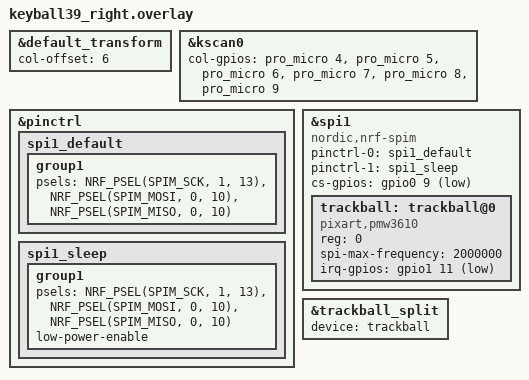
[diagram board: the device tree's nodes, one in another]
/*
 * Copyright (c) 2020 ZMK Contributors
 *
 * SPDX-License-Identifier: MIT
 */
 
#include "keyball39.dtsi"
#include "trackball_split.dtsi"

&default_transform {
    col-offset = <6>;
};

&kscan0 {
	col-gpios
		= <&pro_micro 4 GPIO_ACTIVE_HIGH>
		, <&pro_micro 5 GPIO_ACTIVE_HIGH>
		, <&pro_micro 6 GPIO_ACTIVE_HIGH>
		, <&pro_micro 7 GPIO_ACTIVE_HIGH>
		, <&pro_micro 8 GPIO_ACTIVE_HIGH>
        , <&pro_micro 9 GPIO_ACTIVE_HIGH>
		;
};

&pinctrl {
    spi1_default: spi1_default {
        group1 {
            psels = <NRF_PSEL(SPIM_SCK, 1, 13)>,
                <NRF_PSEL(SPIM_MOSI, 0, 10)>,
                <NRF_PSEL(SPIM_MISO, 0, 10)>;
        };
    };

    spi1_sleep: spi1_sleep {
        group1 {
            psels = <NRF_PSEL(SPIM_SCK, 1, 13)>,
                <NRF_PSEL(SPIM_MOSI, 0, 10)>,
                <NRF_PSEL(SPIM_MISO, 0, 10)>;
            low-power-enable;
        };
    };
};

&spi1 {
    status = "okay";
    compatible = "nordic,nrf-spim";
    pinctrl-0 = <&spi1_default>;
    pinctrl-1 = <&spi1_sleep>;
    pinctrl-names = "default", "sleep";
    cs-gpios = <&gpio0 9 GPIO_ACTIVE_LOW>;

    trackball: trackball@0 {
        status = "okay";
        compatible = "pixart,pmw3610";
        reg = <0>;
        spi-max-frequency = <2000000>;
        irq-gpios = <&gpio1 11 (GPIO_ACTIVE_LOW | GPIO_PULL_UP)>;
        /*
         * No automouse-/scroll-/snipe-layers here: this half is a peripheral
         * and has no layer state. Raw movement is forwarded to the dongle,
         * which applies those input processors (see trackball_split.dtsi).
         */
    };
};

/* Forward raw trackball input to the central (dongle) over the split link. */
&trackball_split {
    device = <&trackball>;
};
